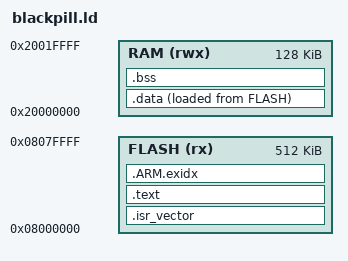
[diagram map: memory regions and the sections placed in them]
/* blackpill.ld: STM32F411CE, 512K flash @0x08000000, 128K SRAM @0x20000000.
 * Vector table: initial SP from the linker, then the `.vectors` array from main.rs. */
ENTRY(reset)
MEMORY
{
    FLASH (rx)  : ORIGIN = 0x08000000, LENGTH = 512K
    RAM   (rwx) : ORIGIN = 0x20000000, LENGTH = 128K
}
_estack = ORIGIN(RAM) + LENGTH(RAM);
SECTIONS
{
    .isr_vector : { LONG(_estack); KEEP(*(.vectors)) } > FLASH
    .text : { *(.text*) *(.rodata*) . = ALIGN(4); } > FLASH
    .ARM.exidx : { *(.ARM.exidx*) } > FLASH
    _sidata = LOADADDR(.data);
    .data : { _sdata = .; *(.data*) . = ALIGN(4); _edata = .; } > RAM AT > FLASH
    .bss (NOLOAD) : { _sbss = .; *(.bss*) *(COMMON) . = ALIGN(4); _ebss = .; } > RAM
}
